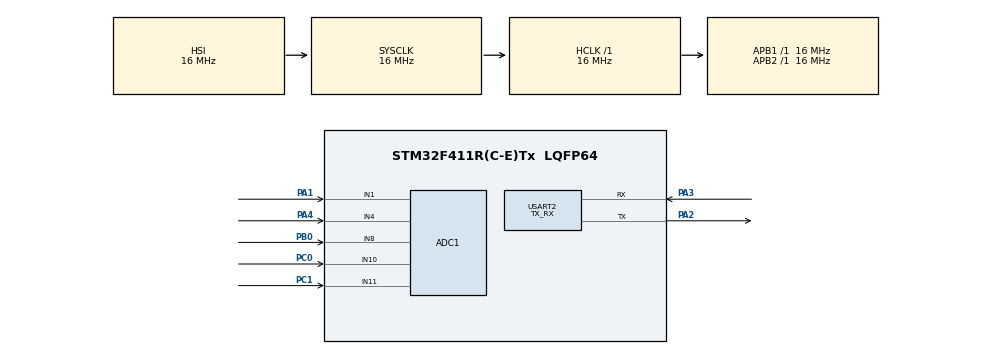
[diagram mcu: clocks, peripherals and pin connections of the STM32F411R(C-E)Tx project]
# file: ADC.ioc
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ADC1.Channel-5\#ChannelRegularConversion=ADC_CHANNEL_1
ADC1.Channel-6\#ChannelRegularConversion=ADC_CHANNEL_4
ADC1.Channel-7\#ChannelRegularConversion=ADC_CHANNEL_8
ADC1.Channel-8\#ChannelRegularConversion=ADC_CHANNEL_11
ADC1.Channel-9\#ChannelRegularConversion=ADC_CHANNEL_10
ADC1.ContinuousConvMode=ENABLE
ADC1.DMAContinuousRequests=ENABLE
ADC1.NbrOfConversion=5
ADC1.NbrOfConversionFlag=1
ADC1.Rank-5\#ChannelRegularConversion=1
ADC1.Rank-6\#ChannelRegularConversion=2
ADC1.Rank-7\#ChannelRegularConversion=3
ADC1.Rank-8\#ChannelRegularConversion=4
ADC1.Rank-9\#ChannelRegularConversion=5
ADC1.SamplingTime-5\#ChannelRegularConversion=ADC_SAMPLETIME_3CYCLES
ADC1.SamplingTime-6\#ChannelRegularConversion=ADC_SAMPLETIME_3CYCLES
ADC1.SamplingTime-7\#ChannelRegularConversion=ADC_SAMPLETIME_3CYCLES
ADC1.SamplingTime-8\#ChannelRegularConversion=ADC_SAMPLETIME_3CYCLES
ADC1.SamplingTime-9\#ChannelRegularConversion=ADC_SAMPLETIME_3CYCLES
ADC1.master=1
Dma.ADC1.0.Direction=DMA_PERIPH_TO_MEMORY
Dma.ADC1.0.FIFOMode=DMA_FIFOMODE_DISABLE
Dma.ADC1.0.Instance=DMA2_Stream0
Dma.ADC1.0.MemDataAlignment=DMA_MDATAALIGN_HALFWORD
Dma.ADC1.0.MemInc=DMA_MINC_ENABLE
Dma.ADC1.0.Mode=DMA_NORMAL
Dma.ADC1.0.PeriphDataAlignment=DMA_PDATAALIGN_HALFWORD
Dma.ADC1.0.PeriphInc=DMA_PINC_DISABLE
Dma.ADC1.0.Priority=DMA_PRIORITY_VERY_HIGH
Dma.Request0=ADC1
Mcu.Family=STM32F4
Mcu.Name=STM32F411R(C-E)Tx
Mcu.Package=LQFP64
NVIC.DMA2_Stream0_IRQn=true\:0\:0\:false\:false\:true\:false\:true
NVIC.PriorityGroup=NVIC_PRIORITYGROUP_4
PA1.Signal=ADCx_IN1
PA2.Mode=Asynchronous
PA2.Signal=USART2_TX
PA3.Mode=Asynchronous
PA3.Signal=USART2_RX
PA4.Signal=ADCx_IN4
PB0.Signal=ADCx_IN8
PC0.Signal=ADCx_IN10
PC1.Signal=ADCx_IN11
PC14-OSC32_IN.Mode=LSE-External-Oscillator
PC14-OSC32_IN.Signal=RCC_OSC32_IN
PC15-OSC32_OUT.Mode=LSE-External-Oscillator
PC15-OSC32_OUT.Signal=RCC_OSC32_OUT
PH0\ -\ OSC_IN.Mode=HSE-External-Oscillator
PH0\ -\ OSC_IN.Signal=RCC_OSC_IN
PH1\ -\ OSC_OUT.Mode=HSE-External-Oscillator
PH1\ -\ OSC_OUT.Signal=RCC_OSC_OUT
ProjectManager.HeapSize=0x200
ProjectManager.StackSize=0x400
ProjectManager.TargetToolchain=STM32CubeIDE
RCC.AHBFreq_Value=16000000
RCC.APB1Freq_Value=16000000
RCC.APB2Freq_Value=16000000
RCC.CortexFreq_Value=16000000
RCC.HSE_VALUE=25000000
RCC.HSI_VALUE=16000000
RCC.SYSCLKFreq_VALUE=16000000
RCC.VCOOutputFreq_Value=192000000
SH.ADCx_IN1.0=ADC1_IN1,IN1
SH.ADCx_IN10.0=ADC1_IN10,IN10
SH.ADCx_IN11.0=ADC1_IN11,IN11
SH.ADCx_IN4.0=ADC1_IN4,IN4
SH.ADCx_IN8.0=ADC1_IN8,IN8
USART2.Mode=MODE_TX_RX
USART2.VirtualMode=VM_ASYNC
board=custom

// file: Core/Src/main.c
/* USER CODE BEGIN Header */
/**
  ******************************************************************************
  * @file           : main.c
  * @brief          : Main program body
  ******************************************************************************
  * @attention
  *
  * <h2><center>&copy; Copyright (c) 2020 STMicroelectronics.
  * All rights reserved.</center></h2>
  *
  * This software component is licensed by ST under BSD 3-Clause license,
  * the "License"; You may not use this file except in compliance with the
  * License. You may obtain a copy of the License at:
  *                        opensource.org/licenses/BSD-3-Clause
  *
  ******************************************************************************
  */
/* USER CODE END Header */
#include "main.h"

/* USER CODE BEGIN Includes */
#include<string.h>
#include<stdio.h>
/* USER CODE END Includes */

ADC_HandleTypeDef hadc1;
DMA_HandleTypeDef hdma_adc1;

UART_HandleTypeDef huart2;

void SystemClock_Config(void);
static void MX_GPIO_Init(void);
static void MX_DMA_Init(void);
static void MX_USART2_UART_Init(void);
static void MX_ADC1_Init(void);

/* USER CODE BEGIN 0 */
uint16_t buffer[5];
/* USER CODE END 0 */

int main(void)
{

  /* MCU Configuration--------------------------------------------------------*/

  /* Reset of all peripherals, Initializes the Flash interface and the Systick. */
  HAL_Init();

  /* Configure the system clock */
  SystemClock_Config();

  /* Initialize all configured peripherals */
  MX_GPIO_Init();
  MX_DMA_Init();
  MX_USART2_UART_Init();
  MX_ADC1_Init();
  /* USER CODE BEGIN 2 */
  char msg[100];

  /* USER CODE END 2 */

  /* Infinite loop */
  /* USER CODE BEGIN WHILE */

  while (1)
  {
	  HAL_ADC_Start_DMA(&hadc1, buffer , 5);
	  HAL_ADC_PollForConversion(&hadc1, HAL_MAX_DELAY);
	  HAL_ADC_Stop_DMA(&hadc1);
	  HAL_Delay(1000);

	  for(int i=0;i<5;i++){
		  buffer[i]=(buffer[i] & 0x0FFF) +(((i+1)<<12)& 0xF000);
	  }
	  sprintf(msg,"%hu\r\n%hu\r\n%hu\r\n%hu\r\n%hu\r\n",buffer[0],buffer[1],buffer[2],buffer[3],buffer[4]);
	  HAL_UART_Transmit(&huart2, (uint8_t*)msg,strlen(msg), HAL_MAX_DELAY);

	  HAL_Delay(1000);

    /* USER CODE END WHILE */

  }
}

void SystemClock_Config(void)
{
  RCC_OscInitTypeDef RCC_OscInitStruct = {0};
  RCC_ClkInitTypeDef RCC_ClkInitStruct = {0};

  /** Configure the main internal regulator output voltage
  */
  __HAL_RCC_PWR_CLK_ENABLE();
  __HAL_PWR_VOLTAGESCALING_CONFIG(PWR_REGULATOR_VOLTAGE_SCALE1);
  /** Initializes the RCC Oscillators according to the specified parameters
  * in the RCC_OscInitTypeDef structure.
  */
  RCC_OscInitStruct.OscillatorType = RCC_OSCILLATORTYPE_HSI;
  RCC_OscInitStruct.HSIState = RCC_HSI_ON;
  RCC_OscInitStruct.HSICalibrationValue = RCC_HSICALIBRATION_DEFAULT;
  RCC_OscInitStruct.PLL.PLLState = RCC_PLL_NONE;
  if (HAL_RCC_OscConfig(&RCC_OscInitStruct) != HAL_OK)
  {
    Error_Handler();
  }
  /** Initializes the CPU, AHB and APB buses clocks
  */
  RCC_ClkInitStruct.ClockType = RCC_CLOCKTYPE_HCLK|RCC_CLOCKTYPE_SYSCLK
                              |RCC_CLOCKTYPE_PCLK1|RCC_CLOCKTYPE_PCLK2;
  RCC_ClkInitStruct.SYSCLKSource = RCC_SYSCLKSOURCE_HSI;
  RCC_ClkInitStruct.AHBCLKDivider = RCC_SYSCLK_DIV1;
  RCC_ClkInitStruct.APB1CLKDivider = RCC_HCLK_DIV1;
  RCC_ClkInitStruct.APB2CLKDivider = RCC_HCLK_DIV1;

  if (HAL_RCC_ClockConfig(&RCC_ClkInitStruct, FLASH_LATENCY_0) != HAL_OK)
  {
    Error_Handler();
  }
}

static void MX_ADC1_Init(void)
{

  ADC_ChannelConfTypeDef sConfig = {0};

  /** Configure the global features of the ADC (Clock, Resolution, Data Alignment and number of conversion)
  */
  hadc1.Instance = ADC1;
  hadc1.Init.ClockPrescaler = ADC_CLOCK_SYNC_PCLK_DIV2;
  hadc1.Init.Resolution = ADC_RESOLUTION_12B;
  hadc1.Init.ScanConvMode = ENABLE;
  hadc1.Init.ContinuousConvMode = ENABLE;
  hadc1.Init.DiscontinuousConvMode = DISABLE;
  hadc1.Init.ExternalTrigConvEdge = ADC_EXTERNALTRIGCONVEDGE_NONE;
  hadc1.Init.ExternalTrigConv = ADC_SOFTWARE_START;
  hadc1.Init.DataAlign = ADC_DATAALIGN_RIGHT;
  hadc1.Init.NbrOfConversion = 5;
  hadc1.Init.DMAContinuousRequests = ENABLE;
  hadc1.Init.EOCSelection = ADC_EOC_SINGLE_CONV;
  if (HAL_ADC_Init(&hadc1) != HAL_OK)
  {
    Error_Handler();
  }
  /** Configure for the selected ADC regular channel its corresponding rank in the sequencer and its sample time.
  */
  sConfig.Channel = ADC_CHANNEL_1;
  sConfig.Rank = 1;
  sConfig.SamplingTime = ADC_SAMPLETIME_3CYCLES;
  if (HAL_ADC_ConfigChannel(&hadc1, &sConfig) != HAL_OK)
  {
    Error_Handler();
  }
  /** Configure for the selected ADC regular channel its corresponding rank in the sequencer and its sample time.
  */
  sConfig.Channel = ADC_CHANNEL_4;
  sConfig.Rank = 2;
  if (HAL_ADC_ConfigChannel(&hadc1, &sConfig) != HAL_OK)
  {
    Error_Handler();
  }
  /** Configure for the selected ADC regular channel its corresponding rank in the sequencer and its sample time.
  */
  sConfig.Channel = ADC_CHANNEL_8;
  sConfig.Rank = 3;
  if (HAL_ADC_ConfigChannel(&hadc1, &sConfig) != HAL_OK)
  {
    Error_Handler();
  }
  /** Configure for the selected ADC regular channel its corresponding rank in the sequencer and its sample time.
  */
  sConfig.Channel = ADC_CHANNEL_11;
  sConfig.Rank = 4;
  if (HAL_ADC_ConfigChannel(&hadc1, &sConfig) != HAL_OK)
  {
    Error_Handler();
  }
  /** Configure for the selected ADC regular channel its corresponding rank in the sequencer and its sample time.
  */
  sConfig.Channel = ADC_CHANNEL_10;
  sConfig.Rank = 5;
  if (HAL_ADC_ConfigChannel(&hadc1, &sConfig) != HAL_OK)
  {
    Error_Handler();
  }

}

static void MX_USART2_UART_Init(void)
{

  huart2.Instance = USART2;
  huart2.Init.BaudRate = 115200;
  huart2.Init.WordLength = UART_WORDLENGTH_8B;
  huart2.Init.StopBits = UART_STOPBITS_1;
  huart2.Init.Parity = UART_PARITY_NONE;
  huart2.Init.Mode = UART_MODE_TX_RX;
  huart2.Init.HwFlowCtl = UART_HWCONTROL_NONE;
  huart2.Init.OverSampling = UART_OVERSAMPLING_16;
  if (HAL_UART_Init(&huart2) != HAL_OK)
  {
    Error_Handler();
  }

}

static void MX_DMA_Init(void)
{

  /* DMA controller clock enable */
  __HAL_RCC_DMA2_CLK_ENABLE();

  /* DMA interrupt init */
  /* DMA2_Stream0_IRQn interrupt configuration */
  HAL_NVIC_SetPriority(DMA2_Stream0_IRQn, 0, 0);
  HAL_NVIC_EnableIRQ(DMA2_Stream0_IRQn);

}

static void MX_GPIO_Init(void)
{

  /* GPIO Ports Clock Enable */
  __HAL_RCC_GPIOC_CLK_ENABLE();
  __HAL_RCC_GPIOH_CLK_ENABLE();
  __HAL_RCC_GPIOA_CLK_ENABLE();
  __HAL_RCC_GPIOB_CLK_ENABLE();

}

void Error_Handler(void)
{
}

/************************ (C) COPYRIGHT STMicroelectronics *****END OF FILE****/
